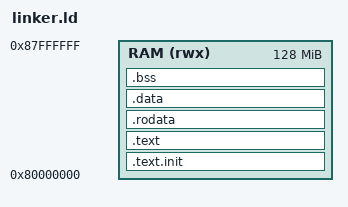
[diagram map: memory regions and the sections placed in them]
OUTPUT_ARCH("riscv")
ENTRY(_start)

MEMORY
{
    RAM (rwx) : ORIGIN = 0x80000000, LENGTH = 128M
}

SECTIONS
{
    .text.init : {
        *(.text.init)
    } > RAM

    .text : {
        *(.text .text.*)
    } > RAM

    .rodata : ALIGN(8) {
        *(.rodata .rodata.*)
        *(.srodata .srodata.*)
    } > RAM

    .data : ALIGN(8) {
        *(.data .data.*)
        *(.sdata .sdata.*)
    } > RAM

    .bss (NOLOAD) : ALIGN(8) {
        __bss_start = .;
        *(.bss .bss.*)
        *(.sbss .sbss.*)
        __bss_end = .;
    } > RAM

    . = ALIGN(8);
    __heap_start = .;

    /* 64KB stack at the top of 128MB RAM */
    __stack_top = ORIGIN(RAM) + LENGTH(RAM);
    __heap_end = __stack_top - 0x10000;

    /DISCARD/ : {
        *(.eh_frame)
        *(.eh_frame_hdr)
    }
}
